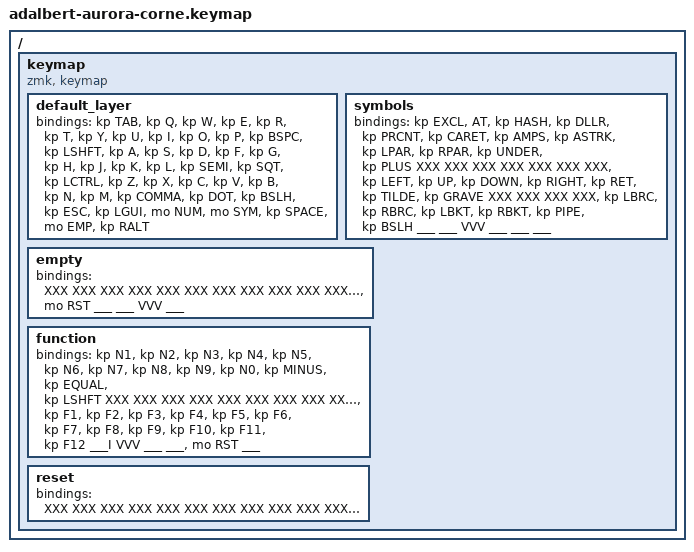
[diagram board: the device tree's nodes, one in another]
/*
 * Copyright (c) 2020 The ZMK Contributors
 *
 * SPDX-License-Identifier: MIT
 */

#include <behaviors.dtsi>
#include <dt-bindings/zmk/keys.h>
#include <dt-bindings/zmk/bt.h>

// Layers

#define QWE 0
#define SYM 1
#define EPM 2
#define FUN 3
#define RST 4

// keys

#define XXX &none
#define ___ &trans
#define VVV &trans

// keyboard layout
//  ╭──────────────┬──────────────┬──────────────┬──────────────┬──────────────┬──────────────╮   ╭──────────────┬─────────────┬──────────────┬──────────────┬─────────────┬──────────────╮
//      &kp TAB         &kp Q          &kp W         &kp E          &kp R          &kp T              &kp Y          &kp U         &kp I          &kp O          &kp P         &kp BSPC
//  ├──────────────┬──────────────┬──────────────┬──────────────┬──────────────┬──────────────┤   ├──────────────┬─────────────┬──────────────┬──────────────┬─────────────┬──────────────┤
//      &kp LSHFT       &kp A          &kp S         &kp D          &kp F          &kp G              &kp H          &kp J         &kp K          &kp L          &kp SEMI      &kp SQT
//  ├──────────────┬──────────────┬──────────────┬──────────────┬──────────────┬──────────────┤   ├──────────────┬─────────────┬──────────────┬──────────────┬─────────────┬──────────────┤
//      &kp LCTRL       &kp Z          &kp X         &kp C          &kp V          &kp B              &kp N          &kp M         &kp COMMA      &kp DOT        &kp BSLH      &kp ESC
//  ╰────────────────────────────────────────────┬──────────────┬──────────────┬──────────────┤   ├──────────────┬─────────────┬──────────────┬───────────────────────────────────────────╯
//                                                     &kp LGUI     &mo NUM        &mo SYM            &kp SPACE      &mo EMP       &kp RALT
//                                               ╰────────────────────────────────────────────╯   ╰───────────────────────────────────────────╯


/ {
  keymap  {
    compatible = "zmk, keymap";

    default_layer {
      bindings = <
        //  ╭──────────────┬──────────────┬──────────────┬──────────────┬──────────────┬──────────────╮   ╭──────────────┬─────────────┬──────────────┬──────────────┬─────────────┬──────────────╮
                &kp TAB         &kp Q          &kp W         &kp E          &kp R          &kp T              &kp Y          &kp U         &kp I          &kp O          &kp P         &kp BSPC
        //  ├──────────────┬──────────────┬──────────────┬──────────────┬──────────────┬──────────────┤   ├──────────────┬─────────────┬──────────────┬──────────────┬─────────────┬──────────────┤
                &kp LSHFT       &kp A          &kp S         &kp D          &kp F          &kp G              &kp H          &kp J         &kp K          &kp L          &kp SEMI      &kp SQT
        //  ├──────────────┬──────────────┬──────────────┬──────────────┬──────────────┬──────────────┤   ├──────────────┬─────────────┬──────────────┬──────────────┬─────────────┬──────────────┤
                &kp LCTRL       &kp Z          &kp X         &kp C          &kp V          &kp B              &kp N          &kp M         &kp COMMA      &kp DOT        &kp BSLH      &kp ESC
        //  ╰────────────────────────────────────────────┬──────────────┬──────────────┬──────────────┤   ├──────────────┬─────────────┬──────────────┬───────────────────────────────────────────╯
                                                             &kp LGUI       &mo NUM        &mo SYM          &kp SPACE        &mo EMP       &kp RALT
        //                                               ╰────────────────────────────────────────────╯   ╰───────────────────────────────────────────╯
      >;    
    };

    symbols {
      bindings = <
        //  ╭──────────────┬──────────────┬──────────────┬──────────────┬──────────────┬──────────────╮   ╭──────────────┬─────────────┬──────────────┬──────────────┬─────────────┬──────────────╮
                &kp EXCL        &AT           &kp HASH       &kp DLLR       &kp PRCNT      &kp CARET          &kp AMPS       &kp ASTRK     &kp LPAR       &kp RPAR      &kp UNDER     &kp PLUS
        //  ├──────────────┬──────────────┬──────────────┬──────────────┬──────────────┬──────────────┤   ├──────────────┬─────────────┬──────────────┬──────────────┬─────────────┬──────────────┤
                  XXX           XXX             XXX            XXX            XXX            XXX                XXX          &kp LEFT      &kp UP         &kp DOWN      &kp RIGHT     &kp RET
        //  ├──────────────┬──────────────┬──────────────┬──────────────┬──────────────┬──────────────┤   ├──────────────┬─────────────┬──────────────┬──────────────┬─────────────┬──────────────┤
                &kp TILDE     &kp GRAVE         XXX            XXX            XXX            XXX              &kp LBRC       &kp RBRC      &kp LBKT       &kp RBKT      &kp PIPE      &kp BSLH
        //  ╰────────────────────────────────────────────┬──────────────┬──────────────┬──────────────┤   ├──────────────┬─────────────┬──────────────┬───────────────────────────────────────────╯
                                                              ___            ___             VVV                ___            ___            ___
        //                                               ╰────────────────────────────────────────────╯   ╰───────────────────────────────────────────╯
      >;    
    };

    empty {
      bindings = <
        //  ╭──────────────┬──────────────┬──────────────┬──────────────┬──────────────┬──────────────╮   ╭──────────────┬─────────────┬──────────────┬──────────────┬─────────────┬──────────────╮
                  XXX           XXX             XXX            XXX            XXX            XXX                XXX           XXX             XXX            XXX          XXX            XXX
        //  ├──────────────┬──────────────┬──────────────┬──────────────┬──────────────┬──────────────┤   ├──────────────┬─────────────┬──────────────┬──────────────┬─────────────┬──────────────┤
                  XXX           XXX             XXX            XXX            XXX            XXX                XXX           XXX             XXX            XXX          XXX            XXX
        //  ├──────────────┬──────────────┬──────────────┬──────────────┬──────────────┬──────────────┤   ├──────────────┬─────────────┬──────────────┬──────────────┬─────────────┬──────────────┤
                  XXX           XXX             XXX            XXX            XXX            XXX                XXX           XXX             XXX            XXX          XXX            XXX
        //  ╰────────────────────────────────────────────┬──────────────┬──────────────┬──────────────┤   ├──────────────┬─────────────┬──────────────┬───────────────────────────────────────────╯
                                                               ___            &mo RST        ___                ___           VVV             ___
        //                                               ╰────────────────────────────────────────────╯   ╰───────────────────────────────────────────╯
      >;    
    };

    function {
      bindings = <
        //  ╭──────────────┬──────────────┬──────────────┬──────────────┬──────────────┬──────────────╮   ╭──────────────┬─────────────┬──────────────┬──────────────┬─────────────┬──────────────╮
                &kp N1          &kp N2          &kp N3         &kp N4         &kp N5         &kp N6             &kp N7        &kp N8          &kp N9        &kp N0      &kp MINUS      &kp EQUAL
        //  ├──────────────┬──────────────┬──────────────┬──────────────┬──────────────┬──────────────┤   ├──────────────┬─────────────┬──────────────┬──────────────┬─────────────┬──────────────┤
                &kp LSHFT        XXX             XXX            XXX            XXX            XXX                XXX           XXX             XXX           XXX           XXX           XXX
        //  ├──────────────┬──────────────┬──────────────┬──────────────┬──────────────┬──────────────┤   ├──────────────┬─────────────┬──────────────┬──────────────┬─────────────┬──────────────┤
                &kp F1          &kp F2          &kp F3         &kp F4         &kp F5         &kp F6             &kp F7        &kp F8          &kp F9        &kp F10      &kp F11      &kp F12
        //  ╰────────────────────────────────────────────┬──────────────┬──────────────┬──────────────┤   ├──────────────┬─────────────┬──────────────┬───────────────────────────────────────────╯
                                                                 ___I          VVV            ___                ___          &mo RST         ___
        //                                               ╰────────────────────────────────────────────╯   ╰───────────────────────────────────────────╯
      >;    
    };

    reset {
      bindings = <
        //  ╭──────────────┬──────────────┬──────────────┬──────────────┬──────────────┬──────────────╮   ╭──────────────┬─────────────┬──────────────┬──────────────┬─────────────┬──────────────╮
                  XXX           XXX             XXX            XXX            XXX            XXX                XXX           XXX             XXX            XXX          XXX            XXX
        //  ├──────────────┬──────────────┬──────────────┬──────────────┬──────────────┬──────────────┤   ├──────────────┬─────────────┬──────────────┬──────────────┬─────────────┬──────────────┤
                  XXX           XXX             XXX            XXX            XXX            XXX                XXX           XXX             XXX            XXX          XXX            XXX
        //  ├──────────────┬──────────────┬──────────────┬──────────────┬──────────────┬──────────────┤   ├──────────────┬─────────────┬──────────────┬──────────────┬─────────────┬──────────────┤
                  XXX           XXX             XXX            XXX            XXX            XXX                XXX           XXX             XXX            XXX          XXX            XXX
        //  ╰────────────────────────────────────────────┬──────────────┬──────────────┬──────────────┤   ├──────────────┬─────────────┬──────────────┬───────────────────────────────────────────╯
                                                               ___            VVV            ___                 ___           VVV             ___
        //                                               ╰────────────────────────────────────────────╯   ╰───────────────────────────────────────────╯
      >;    
    };
  };
};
